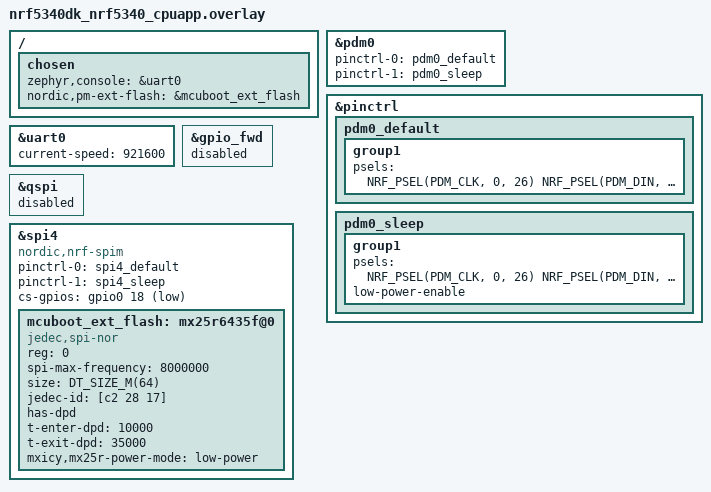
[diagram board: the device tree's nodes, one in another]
/ {
};

&pdm0 {
    status = "okay";

    pinctrl-0 = <&pdm0_default>;
    pinctrl-1 = <&pdm0_sleep>;
    pinctrl-names = "default", "sleep";
};

&pinctrl {

    pdm0_default: pdm0_default {
        group1 {
            psels = <
                NRF_PSEL(PDM_CLK, 0, 26)
                NRF_PSEL(PDM_DIN, 0, 27)
            >;
        };
    };

    pdm0_sleep: pdm0_sleep {
        group1 {
            psels = <
                NRF_PSEL(PDM_CLK, 0, 26)
                NRF_PSEL(PDM_DIN, 0, 27)
            >;

            low-power-enable;
        };
    };
};

/ {
    chosen {
        zephyr,console = &uart0;
    };
};

&uart0 {
    current-speed = <921600>;
    status = "okay";
};


&gpio_fwd {
    status = "disabled";
};

&qspi {
    status = "disabled";
    /delete-node/ mx25r64;
};

&spi4 {
    compatible = "nordic,nrf-spim";
    status = "okay";

    pinctrl-0 = <&spi4_default>;
    pinctrl-1 = <&spi4_sleep>;
    pinctrl-names = "default", "sleep";

    cs-gpios = <&gpio0 18 GPIO_ACTIVE_LOW>;

    mcuboot_ext_flash: mx25r6435f@0 {
        compatible = "jedec,spi-nor";
        status = "okay";

        reg = <0>;
        spi-max-frequency = <8000000>;

        size = <DT_SIZE_M(64)>;

        jedec-id = [c2 28 17];

        has-dpd;
        t-enter-dpd = <10000>;
        t-exit-dpd = <35000>;

        mxicy,mx25r-power-mode = "low-power";
    };
};

/
{
    chosen {
        nordic,pm-ext-flash = &mcuboot_ext_flash;
    };
};
